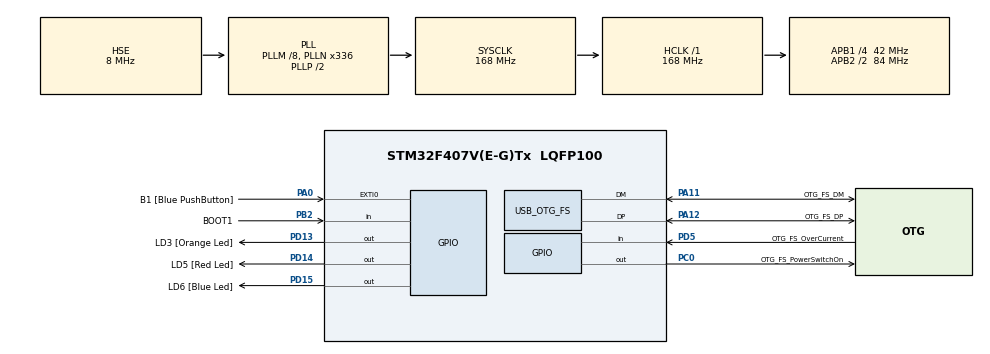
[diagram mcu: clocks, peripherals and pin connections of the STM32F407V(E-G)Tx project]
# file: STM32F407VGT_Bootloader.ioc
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Mcu.Family=STM32F4
PA11.GPIO_Speed=GPIO_SPEED_FREQ_LOW
USB_DEVICE.CLASS_NAME_FS=CDC
PH0-OSC_IN.Signal=RCC_OSC_IN
RCC.CortexFreq_Value=168000000
PD15.GPIO_Speed=GPIO_SPEED_FREQ_LOW
PA14.GPIO_Label=SWCLK
PC0.GPIO_Label=OTG_FS_PowerSwitchOn
PA11.Mode=Device_Only
USB_DEVICE.VirtualMode-CDC_FS=Cdc
PA11.GPIO_PuPd=GPIO_NOPULL
PC15-OSC32_OUT.GPIO_Label=PC15-OSC32_OUT
RCC.SYSCLKSource=RCC_SYSCLKSOURCE_PLLCLK
ProjectManager.StackSize=0x400
PD13.Signal=GPIO_Output
PD14.GPIO_Speed=GPIO_SPEED_FREQ_LOW
PA12.Signal=USB_OTG_FS_DP
RCC.HCLKFreq_Value=168000000
RCC.APB2TimFreq_Value=168000000
RCC.AHBFreq_Value=168000000
PH0-OSC_IN.Mode=HSE-External-Oscillator
PH0-OSC_IN.GPIO_Label=PH0-OSC_IN
RCC.HSE_VALUE=8000000
PB2.Signal=GPIO_Input
PC14-OSC32_IN.Mode=LSE-External-Oscillator
PA14.Mode=Serial_Wire
USB_DEVICE.MANUFACTURER_STRING-CDC_FS=Yakamooda GmbH
PD5.GPIO_Mode=GPIO_MODE_INPUT
PD14.GPIO_PuPd=GPIO_NOPULL
PB2.GPIO_PuPd=GPIO_NOPULL
USB_DEVICE.APP_RX_DATA_SIZE-CDC_FS=1000
PH1-OSC_OUT.Mode=HSE-External-Oscillator
PD13.GPIO_Label=LD3 [Orange Led]
Mcu.Package=LQFP100
PD5.GPIO_Label=OTG_FS_OverCurrent
NVIC.OTG_FS_IRQn=true\:0\:0\:false\:false\:true\:false\:true
PD15.GPIO_PuPd=GPIO_NOPULL
USB_OTG_FS.VirtualMode=Device_Only
RCC.APB2CLKDivider=RCC_HCLK_DIV2
RCC.APB1TimFreq_Value=84000000
PC14-OSC32_IN.GPIO_Label=PC14-OSC32_IN
PC0.GPIO_PuPd=GPIO_NOPULL
PA12.GPIO_PuPd=GPIO_NOPULL
PD15.Signal=GPIO_Output
PC0.PinState=GPIO_PIN_SET
PA12.GPIO_Speed=GPIO_SPEED_FREQ_LOW
PC15-OSC32_OUT.Mode=LSE-External-Oscillator
PD15.GPIO_Label=LD6 [Blue Led]
USB_DEVICE.VirtualModeFS=Cdc_FS
PA11.GPIO_Label=OTG_FS_DM
PD5.Signal=GPIO_Input
PC0.Signal=GPIO_Output
RCC.APB1CLKDivider=RCC_HCLK_DIV4
PC14-OSC32_IN.Signal=RCC_OSC32_IN
PA0-WKUP.GPIO_ModeDefaultEXTI=GPIO_MODE_EVT_RISING
PA12.GPIO_Label=OTG_FS_DP
PA0-WKUP.GPIO_Label=B1 [Blue PushButton]
PA0-WKUP.Signal=GPXTI0
PA13.Signal=SYS_JTMS-SWDIO
PC0.GPIO_Speed=GPIO_SPEED_FREQ_LOW
ProjectManager.TargetToolchain=STM32CubeIDE
USB_DEVICE.PRODUCT_STRING_CDC_FS=Yakamooda Flasher ComPort
USB_DEVICE.APP_TX_DATA_SIZE-CDC_FS=1000
VP_USB_DEVICE_VS_USB_DEVICE_CDC_FS.Mode=CDC_FS
PC15-OSC32_OUT.Signal=RCC_OSC32_OUT
board=STM32F407G-DISC1
PD13.GPIO_Speed=GPIO_SPEED_FREQ_LOW
RCC.VCOOutputFreq_Value=336000000
PA12.GPIO_Mode=GPIO_MODE_AF_PP
RCC.APB2Freq_Value=84000000
PB2.GPIO_Mode=GPIO_MODE_INPUT
PH1-OSC_OUT.Signal=RCC_OSC_OUT
PD13.GPIO_PuPd=GPIO_NOPULL
PD5.GPIO_PuPd=GPIO_NOPULL
PD14.GPIO_Label=LD5 [Red Led]
PH1-OSC_OUT.GPIO_Label=PH1-OSC_OUT
PA13.Mode=Serial_Wire
Mcu.Name=STM32F407V(E-G)Tx
PA13.GPIO_Label=SWDIO
PD14.Signal=GPIO_Output
RCC.48MHZClocksFreq_Value=48000000
RCC.SYSCLKFreq_VALUE=168000000
PA12.Mode=Device_Only
PA11.Signal=USB_OTG_FS_DM
PA14.Signal=SYS_JTCK-SWCLK
PB2.GPIO_Label=BOOT1
ProjectManager.HeapSize=0x200
RCC.HSI_VALUE=16000000
RCC.PLLQ=7
NVIC.PriorityGroup=NVIC_PRIORITYGROUP_0
RCC.PLLM=8
RCC.PLLN=336
PA0-WKUP.GPIO_PuPd=GPIO_NOPULL
PA11.GPIO_Mode=GPIO_MODE_AF_PP
RCC.APB1Freq_Value=42000000

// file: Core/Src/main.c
/* USER CODE BEGIN Header */
/**
 ******************************************************************************
 * @file           : main.c
 * @brief          : Main program body
 ******************************************************************************
 * @attention
 *
 * <h2><center>&copy; Copyright (c) 2021 STMicroelectronics.
 * All rights reserved.</center></h2>
 *
 * This software component is licensed by ST under Ultimate Liberty license
 * SLA0044, the "License"; You may not use this file except in compliance with
 * the License. You may obtain a copy of the License at:
 *                             www.st.com/SLA0044
 *
 ******************************************************************************
 */
/* USER CODE END Header */
#include "main.h"
#include "usb_device.h"

/* USER CODE BEGIN Includes */
#include "bootloader.h"
/* USER CODE END Includes */

void SystemClock_Config(void);
static void MX_GPIO_Init(void);

int main(void)
{

  /* MCU Configuration--------------------------------------------------------*/

  /* Reset of all peripherals, Initializes the Flash interface and the Systick. */
  HAL_Init();

  /* Configure the system clock */
  SystemClock_Config();

  /* Initialize all configured peripherals */
  MX_GPIO_Init();
  MX_USB_DEVICE_Init();
  /* USER CODE BEGIN 2 */
	bootloaderInit();
  /* USER CODE END 2 */

  /* Infinite loop */
	while (1) {

	}
}

void SystemClock_Config(void)
{
  RCC_OscInitTypeDef RCC_OscInitStruct = {0};
  RCC_ClkInitTypeDef RCC_ClkInitStruct = {0};

  /** Configure the main internal regulator output voltage
  */
  __HAL_RCC_PWR_CLK_ENABLE();
  __HAL_PWR_VOLTAGESCALING_CONFIG(PWR_REGULATOR_VOLTAGE_SCALE1);
  /** Initializes the RCC Oscillators according to the specified parameters
  * in the RCC_OscInitTypeDef structure.
  */
  RCC_OscInitStruct.OscillatorType = RCC_OSCILLATORTYPE_HSE;
  RCC_OscInitStruct.HSEState = RCC_HSE_ON;
  RCC_OscInitStruct.PLL.PLLState = RCC_PLL_ON;
  RCC_OscInitStruct.PLL.PLLSource = RCC_PLLSOURCE_HSE;
  RCC_OscInitStruct.PLL.PLLM = 8;
  RCC_OscInitStruct.PLL.PLLN = 336;
  RCC_OscInitStruct.PLL.PLLP = RCC_PLLP_DIV2;
  RCC_OscInitStruct.PLL.PLLQ = 7;
  if (HAL_RCC_OscConfig(&RCC_OscInitStruct) != HAL_OK)
  {
    Error_Handler();
  }
  /** Initializes the CPU, AHB and APB buses clocks
  */
  RCC_ClkInitStruct.ClockType = RCC_CLOCKTYPE_HCLK|RCC_CLOCKTYPE_SYSCLK
                              |RCC_CLOCKTYPE_PCLK1|RCC_CLOCKTYPE_PCLK2;
  RCC_ClkInitStruct.SYSCLKSource = RCC_SYSCLKSOURCE_PLLCLK;
  RCC_ClkInitStruct.AHBCLKDivider = RCC_SYSCLK_DIV1;
  RCC_ClkInitStruct.APB1CLKDivider = RCC_HCLK_DIV4;
  RCC_ClkInitStruct.APB2CLKDivider = RCC_HCLK_DIV2;

  if (HAL_RCC_ClockConfig(&RCC_ClkInitStruct, FLASH_LATENCY_5) != HAL_OK)
  {
    Error_Handler();
  }
}

static void MX_GPIO_Init(void)
{
  GPIO_InitTypeDef GPIO_InitStruct = {0};

  /* GPIO Ports Clock Enable */
  __HAL_RCC_GPIOC_CLK_ENABLE();
  __HAL_RCC_GPIOH_CLK_ENABLE();
  __HAL_RCC_GPIOA_CLK_ENABLE();
  __HAL_RCC_GPIOB_CLK_ENABLE();
  __HAL_RCC_GPIOD_CLK_ENABLE();

  /*Configure GPIO pin Output Level */
  HAL_GPIO_WritePin(OTG_FS_PowerSwitchOn_GPIO_Port, OTG_FS_PowerSwitchOn_Pin, GPIO_PIN_SET);

  /*Configure GPIO pin Output Level */
  HAL_GPIO_WritePin(GPIOD, LD3_Pin|LD5_Pin|LD6_Pin, GPIO_PIN_RESET);

  /*Configure GPIO pin : OTG_FS_PowerSwitchOn_Pin */
  GPIO_InitStruct.Pin = OTG_FS_PowerSwitchOn_Pin;
  GPIO_InitStruct.Mode = GPIO_MODE_OUTPUT_PP;
  GPIO_InitStruct.Pull = GPIO_NOPULL;
  GPIO_InitStruct.Speed = GPIO_SPEED_FREQ_LOW;
  HAL_GPIO_Init(OTG_FS_PowerSwitchOn_GPIO_Port, &GPIO_InitStruct);

  /*Configure GPIO pin : B1_Pin */
  GPIO_InitStruct.Pin = B1_Pin;
  GPIO_InitStruct.Mode = GPIO_MODE_EVT_RISING;
  GPIO_InitStruct.Pull = GPIO_NOPULL;
  HAL_GPIO_Init(B1_GPIO_Port, &GPIO_InitStruct);

  /*Configure GPIO pin : BOOT1_Pin */
  GPIO_InitStruct.Pin = BOOT1_Pin;
  GPIO_InitStruct.Mode = GPIO_MODE_INPUT;
  GPIO_InitStruct.Pull = GPIO_NOPULL;
  HAL_GPIO_Init(BOOT1_GPIO_Port, &GPIO_InitStruct);

  /*Configure GPIO pins : LD3_Pin LD5_Pin LD6_Pin */
  GPIO_InitStruct.Pin = LD3_Pin|LD5_Pin|LD6_Pin;
  GPIO_InitStruct.Mode = GPIO_MODE_OUTPUT_PP;
  GPIO_InitStruct.Pull = GPIO_NOPULL;
  GPIO_InitStruct.Speed = GPIO_SPEED_FREQ_LOW;
  HAL_GPIO_Init(GPIOD, &GPIO_InitStruct);

  /*Configure GPIO pin : OTG_FS_OverCurrent_Pin */
  GPIO_InitStruct.Pin = OTG_FS_OverCurrent_Pin;
  GPIO_InitStruct.Mode = GPIO_MODE_INPUT;
  GPIO_InitStruct.Pull = GPIO_NOPULL;
  HAL_GPIO_Init(OTG_FS_OverCurrent_GPIO_Port, &GPIO_InitStruct);

}

void Error_Handler(void)
{
	__disable_irq();
	while (1) {
	}
}

/************************ (C) COPYRIGHT STMicroelectronics *****END OF FILE****/
